AUTOSAR XML (schema 4-2-2)
package /AUTOLIV/SoftwareComponents/STM
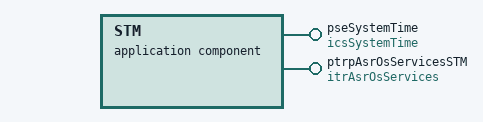
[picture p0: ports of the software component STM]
  application sw component type STM: category=SWC  # STM_AC_SystemTimeManagement
    provide port pseSystemTime: server-com-spec{operation=ReadAbsoluteSystemTime, queue-length=1}, provided-interface=icsSystemTime  # # Architecture Element ID ARCH_SW_STM_pseSystemTime_ReadAbsoluteSystemTime # Description - The runnable shall return the absolute system time in ms of the ECUs # Data Flow ## Inputs: ## Outputs - {Absolute System Time} # Linked Runnable - STM_runReadAbsoluteSystemTime # Traceability
    provide port ptrpAsrOsServicesSTM: provided-interface=itrAsrOsServices  # # Architecture Element ID ARCH_SW_STM_ptrpAsrOsServices # Description - The runnable shall be called each 5ms in order to increment the ECUs system time # Data Flow ## Inputs: ## Outputs # Linked Runnable - STM_runIncreaseSystemTime # Traceability
